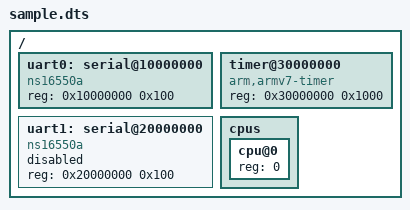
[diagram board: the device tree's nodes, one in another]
/dts-v1/;

/ {
    #address-cells = <1>;
    #size-cells = <1>;

    // 1. 显式 enabled 的节点
    uart0: serial@10000000 {
        compatible = "ns16550a";
        reg = <0x10000000 0x100>;
        status = "okay";
    };

    // 2. 显式 disabled 的节点 (不应输出)
    uart1: serial@20000000 {
        compatible = "ns16550a";
        reg = <0x20000000 0x100>;
        status = "disabled";
    };

    // 3. 默认 enabled 的节点 (没有 status 属性，默认为开启)
    timer@30000000 {
        compatible = "arm,armv7-timer";
        reg = <0x30000000 0x1000>;
    };

    // 4. 没有 reg 属性的节点 (即使开启也不应崩溃)
    cpus {
        #address-cells = <1>;
        #size-cells = <0>;
        cpu@0 {
            device_type = "cpu";
            reg = <0>;
            status = "okay";
        };
    };
};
